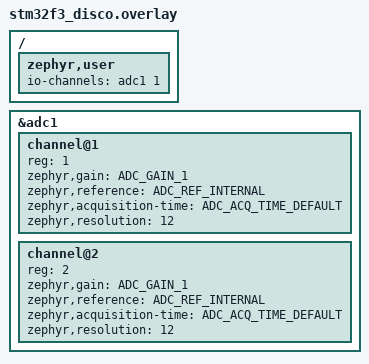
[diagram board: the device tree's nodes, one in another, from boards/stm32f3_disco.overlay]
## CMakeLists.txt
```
# SPDX-License-Identifier: Apache-2.0

cmake_minimum_required(VERSION 3.20.0)

find_package(Zephyr REQUIRED HINTS $ENV{ZEPHYR_BASE})
project(ADC)

target_sources(app PRIVATE src/main.cpp)
```

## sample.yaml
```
sample:
  name: ADC driver sample
tests:
  sample.drivers.adc:
    tags:
      - adc
    depends_on: adc
    platform_allow:
      - stm32f3_disco
      - nucleo_l073rz
      - disco_l475_iot1
      - cc3220sf_launchxl
      - cc3235sf_launchxl
      - cy8cproto_063_ble
      - stm32l496g_disco
      - stm32h735g_disco
      - nrf51dk_nrf51422
      - nrf52840dk_nrf52840
      - mec172xevb_assy6906
      - gd32f350r_eval
      - gd32f450i_eval
      - gd32vf103v_eval
      - gd32f403z_eval
      - esp32_devkitc_wroom
      - esp32_devkitc_wrover
      - esp32s2_saola
      - esp32c3_devkitm
      - gd32l233r_eval
      - lpcxpresso55s36
      - mr_canhubk3
      - longan_nano
      - longan_nano_lite
    integration_platforms:
      - nucleo_l073rz
      - nrf52840dk_nrf52840
    harness: console
    timeout: 10
    harness_config:
      type: multi_line
      regex:
        - "ADC reading\\[\\d+\\]:"
        - "- .+, channel \\d+: -?\\d+"
```

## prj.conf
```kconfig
CONFIG_ADC=y
CONFIG_CBPRINTF_FP_SUPPORT=y
```

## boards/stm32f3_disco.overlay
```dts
/* Copyright (c) 2021 STMicroelectronics
   SPDX-License-Identifier: Apache-2.0 */

 / {
	zephyr,user {
		/* adjust channel number according to pinmux in board.dts */
		io-channels = <&adc1 1>;
	};
};

&adc1 {
	#address-cells = <1>;
	#size-cells = <0>;

	channel@1 {
		reg = <1>;
		zephyr,gain = "ADC_GAIN_1";
		zephyr,reference = "ADC_REF_INTERNAL";
		zephyr,acquisition-time = <ADC_ACQ_TIME_DEFAULT>;
		zephyr,resolution = <12>;
	};

	channel@2 {
		reg = <2>;
		zephyr,gain = "ADC_GAIN_1";
		zephyr,reference = "ADC_REF_INTERNAL";
		zephyr,acquisition-time = <ADC_ACQ_TIME_DEFAULT>;
		zephyr,resolution = <12>;
	};
};
```

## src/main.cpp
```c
/*
 * Copyright (c) 2020 Libre Solar Technologies GmbH
 *
 * SPDX-License-Identifier: Apache-2.0
 */

#include <inttypes.h>
#include <stddef.h>
#include <stdint.h>
#include <stdio.h>
#include <math.h>

#include <zephyr/device.h>
#include <zephyr/devicetree.h>
#include <zephyr/drivers/adc.h>
#include <zephyr/kernel.h>
#include <zephyr/sys/printk.h>
#include <zephyr/sys/util.h>

#if !DT_NODE_EXISTS(DT_PATH(zephyr_user)) || \
	!DT_NODE_HAS_PROP(DT_PATH(zephyr_user), io_channels)
#error "No suitable devicetree overlay specified"
#endif

#define DT_SPEC_AND_COMMA(node_id, prop, idx) \
	ADC_DT_SPEC_GET_BY_IDX(node_id, idx),

	/* Data of ADC io-channels specified in devicetree. */
	static const struct adc_dt_spec adc_channels[] = {
		DT_FOREACH_PROP_ELEM(DT_PATH(zephyr_user), io_channels, DT_SPEC_AND_COMMA)};

int main(void)
{
	int err;
	uint16_t buf;
	struct adc_sequence sequence = {
		.buffer = &buf,
		/* buffer size in bytes, not number of samples */
		.buffer_size = sizeof(buf),
	};

	/* Configure channels individually prior to sampling. */
	for (size_t i = 0U; i < ARRAY_SIZE(adc_channels); i++) {
		if (!adc_is_ready_dt(&adc_channels[i])) {
			printk("ADC controller device %s not ready\n", adc_channels[i].dev->name);
			return 0;
		}

		err = adc_channel_setup_dt(&adc_channels[i]);
		if (err < 0) {
			printk("Could not setup channel #%d (%d)\n", i, err);
			return 0;
		}
	}

	while (1)
	{
		for (size_t i = 0U; i < ARRAY_SIZE(adc_channels); i++) {
			int32_t val_mv;

			(void)adc_sequence_init_dt(&adc_channels[i], &sequence);

			err = adc_read_dt(&adc_channels[i], &sequence);
			if (err < 0) {
				printk("Could not read (%d)\n", err);
				continue;
			}

			/*
			 * If using differential mode, the 16 bit value
			 * in the ADC sample buffer should be a signed 2's
			 * complement value.
			 */
			if (adc_channels[i].channel_cfg.differential) {
				val_mv = (int32_t)((int16_t)buf);
			} else {
				val_mv = (int32_t)buf;
			}
			// printk(" %" PRId32 " C\n", val_mv);
			err = adc_raw_to_millivolts_dt(&adc_channels[i], &val_mv);
			// /* conversion to mV may not be supported, skip if not */
			if (err < 0) {
				printk(" (value in mV not available)\n");
			}

			float sum = 0;
			for (int i = 0; i < 100; i++) {
				sum += val_mv;
				k_sleep(K_MSEC(1));
			}
			sum = sum / 1000;
			printk("Temperature in Celcius = %0.2f C\n", sum);
		}
		k_sleep(K_MSEC(100));
	}
	
	return 0;
}
```
